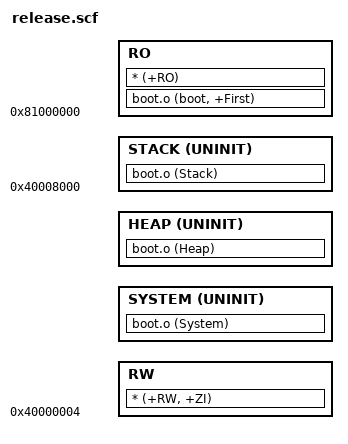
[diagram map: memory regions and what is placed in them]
;/******************************************************Copyright (c)**************************************************
;**                                              胆怯是阻止一切可能的根本缘由
;**
;**                                             E-Mail: ChinaFengliang@163.com
;**
;**---------File Information--------------------------------------------------------------------------------------------
;** File name:            debug.scf
;** Last version:         V1.00
;** Descriptions:         分散加载文件.
;** Hardware platform:    LPC1768 
;** System information:   片内SRAM空间  : 0x1000 0000 ~ 0x1000 8000 (共32K)
;**                                       0x2007 C000 ~ 0x2008 4000 (共32K)
;**	                     片内Flash空间 : 0x0000 0000 ~ 0x0008 0000 (共512K)
;**
;**--------------------------------------------------------------------------------------------------------------------
;** Created by:           Fengliang
;** Created date:         2010年9月4日  9:7:30
;** Version:              V1.00
;** Descriptions:         The original version
;**
;**--------------------------------------------------------------------------------------------------------------------
;** Modified by:		  
;** Modified date:		  
;** Version:
;** Descriptions:
;**
;*********************************************************************************************************************/

main2460 0x81000000
{
    RO 0x81000000
    {
        boot.o (boot, +First)
        * (+RO)
    }

    RW 0x40000004
    {
        * (+RW, +ZI)
    }

    SYSTEM +0 UNINIT
    {
        boot.o (System)
    }

    HEAP +0 UNINIT
    {
        boot.o (Heap)
    }

	STACK 0x40008000 UNINIT
	{
		boot.o (Stack)
	}

}

;/*********************************************************************************************************************
;                                                    END OF FILE
;*********************************************************************************************************************/


